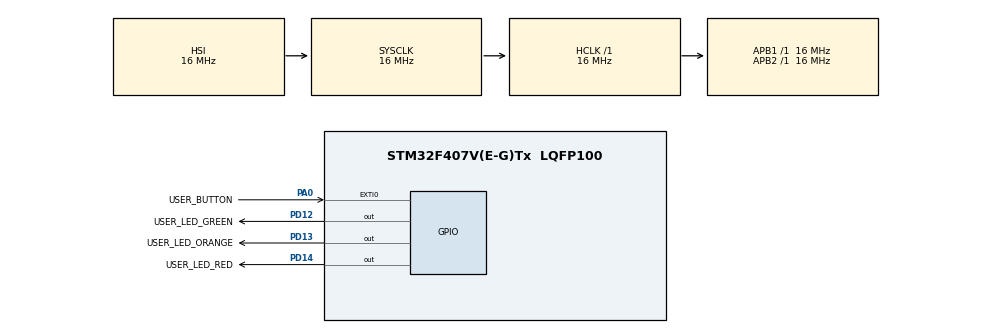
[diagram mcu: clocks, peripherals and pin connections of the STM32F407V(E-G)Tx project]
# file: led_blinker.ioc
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Mcu.Family=STM32F4
Mcu.Name=STM32F407V(E-G)Tx
Mcu.Package=LQFP100
NVIC.EXTI0_IRQn=true\:0\:0\:false\:false\:true\:true\:true\:true
NVIC.PriorityGroup=NVIC_PRIORITYGROUP_4
NVIC.TIM6_DAC_IRQn=true\:0\:0\:false\:false\:true\:true\:true\:true
PA0-WKUP.GPIO_Label=USER_BUTTON
PA0-WKUP.Signal=GPXTI0
PD12.GPIO_Label=USER_LED_GREEN
PD12.Signal=GPIO_Output
PD13.GPIO_Label=USER_LED_ORANGE
PD13.Signal=GPIO_Output
PD14.GPIO_Label=USER_LED_RED
PD14.Signal=GPIO_Output
ProjectManager.HeapSize=0x200
ProjectManager.StackSize=0x400
ProjectManager.TargetToolchain=STM32CubeIDE
RCC.AHBFreq_Value=16000000
RCC.APB1Freq_Value=16000000
RCC.APB2Freq_Value=16000000
RCC.CortexFreq_Value=16000000
RCC.HSE_VALUE=25000000
RCC.HSI_VALUE=16000000
RCC.LSE_VALUE=32768
RCC.SYSCLKFreq_VALUE=16000000
RCC.VCOOutputFreq_Value=192000000
TIM6.Period=31249
TIM6.Prescaler=255
TIM6.TIM_MasterOutputTrigger=TIM_TRGO_UPDATE
VP_TIM6_VS_ClockSourceINT.Mode=Enable_Timer
board=custom

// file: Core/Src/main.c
/* USER CODE BEGIN Header */
/**
  ******************************************************************************
  * @file           : main.c
  * @brief          : Main program body
  ******************************************************************************
  * @attention
  *
  * Copyright (c) 2025 STMicroelectronics.
  * All rights reserved.
  *
  * This software is licensed under terms that can be found in the LICENSE file
  * in the root directory of this software component.
  * If no LICENSE file comes with this software, it is provided AS-IS.
  *
  ******************************************************************************
  */
/* USER CODE END Header */
#include "main.h"

TIM_HandleTypeDef htim6;

void SystemClock_Config(void);
static void MX_GPIO_Init(void);
static void MX_TIM6_Init(void);

/* USER CODE BEGIN 0 */
void HAL_TIM_PeriodElapsedCallback(TIM_HandleTypeDef *htim)
{
  /* Prevent unused argument(s) compilation warning */
  UNUSED(htim);
  //Timer will toggle green and orange led
  HAL_GPIO_TogglePin(USER_LED_GREEN_GPIO_Port, USER_LED_GREEN_Pin);
  HAL_GPIO_TogglePin(USER_LED_ORANGE_GPIO_Port, USER_LED_ORANGE_Pin);

}

void HAL_GPIO_EXTI_Callback(uint16_t GPIO_Pin)
{
  /* Prevent unused argument(s) compilation warning */
  UNUSED(GPIO_Pin);
  //button will toggle red led
  HAL_GPIO_TogglePin(USER_LED_RED_GPIO_Port, USER_LED_RED_Pin);

}

/* USER CODE END 0 */

int main(void)
{

  /* MCU Configuration--------------------------------------------------------*/

  /* Reset of all peripherals, Initializes the Flash interface and the Systick. */
  HAL_Init();

  /* Configure the system clock */
  SystemClock_Config();

  /* Initialize all configured peripherals */
  MX_GPIO_Init();
  MX_TIM6_Init();
  /* USER CODE BEGIN 2 */
  HAL_TIM_Base_Start_IT(&htim6);
  /* USER CODE END 2 */

  /* Infinite loop */
  while (1)
  {

  }
}

void SystemClock_Config(void)
{
  RCC_OscInitTypeDef RCC_OscInitStruct = {0};
  RCC_ClkInitTypeDef RCC_ClkInitStruct = {0};

  /** Configure the main internal regulator output voltage
  */
  __HAL_RCC_PWR_CLK_ENABLE();
  __HAL_PWR_VOLTAGESCALING_CONFIG(PWR_REGULATOR_VOLTAGE_SCALE1);

  /** Initializes the RCC Oscillators according to the specified parameters
  * in the RCC_OscInitTypeDef structure.
  */
  RCC_OscInitStruct.OscillatorType = RCC_OSCILLATORTYPE_HSI;
  RCC_OscInitStruct.HSIState = RCC_HSI_ON;
  RCC_OscInitStruct.HSICalibrationValue = RCC_HSICALIBRATION_DEFAULT;
  RCC_OscInitStruct.PLL.PLLState = RCC_PLL_NONE;
  if (HAL_RCC_OscConfig(&RCC_OscInitStruct) != HAL_OK)
  {
    Error_Handler();
  }

  /** Initializes the CPU, AHB and APB buses clocks
  */
  RCC_ClkInitStruct.ClockType = RCC_CLOCKTYPE_HCLK|RCC_CLOCKTYPE_SYSCLK
                              |RCC_CLOCKTYPE_PCLK1|RCC_CLOCKTYPE_PCLK2;
  RCC_ClkInitStruct.SYSCLKSource = RCC_SYSCLKSOURCE_HSI;
  RCC_ClkInitStruct.AHBCLKDivider = RCC_SYSCLK_DIV1;
  RCC_ClkInitStruct.APB1CLKDivider = RCC_HCLK_DIV1;
  RCC_ClkInitStruct.APB2CLKDivider = RCC_HCLK_DIV1;

  if (HAL_RCC_ClockConfig(&RCC_ClkInitStruct, FLASH_LATENCY_0) != HAL_OK)
  {
    Error_Handler();
  }
}

static void MX_TIM6_Init(void)
{

  TIM_MasterConfigTypeDef sMasterConfig = {0};

  htim6.Instance = TIM6;
  htim6.Init.Prescaler = 255;
  htim6.Init.CounterMode = TIM_COUNTERMODE_UP;
  htim6.Init.Period = 31249;
  htim6.Init.AutoReloadPreload = TIM_AUTORELOAD_PRELOAD_DISABLE;
  if (HAL_TIM_Base_Init(&htim6) != HAL_OK)
  {
    Error_Handler();
  }
  sMasterConfig.MasterOutputTrigger = TIM_TRGO_UPDATE;
  sMasterConfig.MasterSlaveMode = TIM_MASTERSLAVEMODE_DISABLE;
  if (HAL_TIMEx_MasterConfigSynchronization(&htim6, &sMasterConfig) != HAL_OK)
  {
    Error_Handler();
  }

}

static void MX_GPIO_Init(void)
{
  GPIO_InitTypeDef GPIO_InitStruct = {0};

  /* GPIO Ports Clock Enable */
  __HAL_RCC_GPIOA_CLK_ENABLE();
  __HAL_RCC_GPIOD_CLK_ENABLE();

  /*Configure GPIO pin Output Level */
  HAL_GPIO_WritePin(GPIOD, USER_LED_GREEN_Pin|USER_LED_ORANGE_Pin|USER_LED_RED_Pin, GPIO_PIN_RESET);

  /*Configure GPIO pin : USER_BUTTON_Pin */
  GPIO_InitStruct.Pin = USER_BUTTON_Pin;
  GPIO_InitStruct.Mode = GPIO_MODE_IT_RISING;
  GPIO_InitStruct.Pull = GPIO_NOPULL;
  HAL_GPIO_Init(USER_BUTTON_GPIO_Port, &GPIO_InitStruct);

  /*Configure GPIO pins : USER_LED_GREEN_Pin USER_LED_ORANGE_Pin USER_LED_RED_Pin */
  GPIO_InitStruct.Pin = USER_LED_GREEN_Pin|USER_LED_ORANGE_Pin|USER_LED_RED_Pin;
  GPIO_InitStruct.Mode = GPIO_MODE_OUTPUT_PP;
  GPIO_InitStruct.Pull = GPIO_NOPULL;
  GPIO_InitStruct.Speed = GPIO_SPEED_FREQ_LOW;
  HAL_GPIO_Init(GPIOD, &GPIO_InitStruct);

  /* EXTI interrupt init*/
  HAL_NVIC_SetPriority(EXTI0_IRQn, 0, 0);
  HAL_NVIC_EnableIRQ(EXTI0_IRQn);

}

void Error_Handler(void)
{
  __disable_irq();
  while (1)
  {
  }
}
